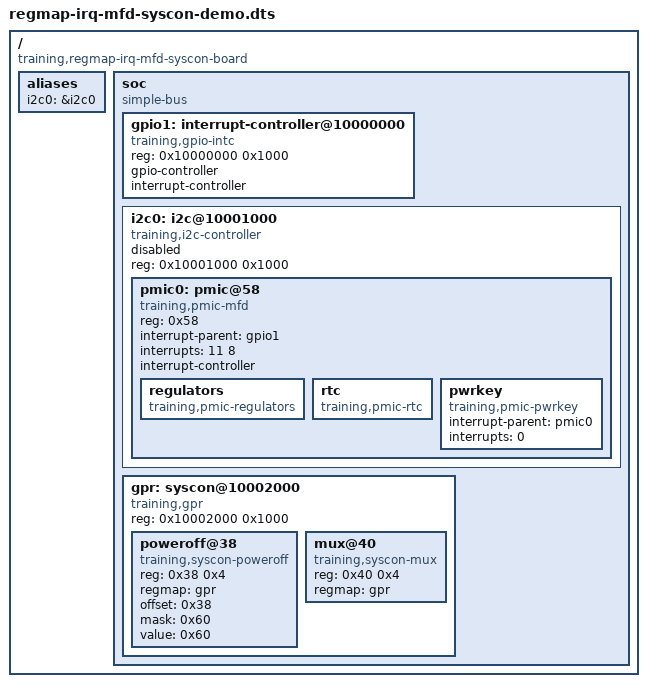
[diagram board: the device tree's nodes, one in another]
/dts-v1/;

/ {
	compatible = "training,regmap-irq-mfd-syscon-board";
	#address-cells = <1>;
	#size-cells = <1>;

	aliases {
		i2c0 = &i2c0;
	};

	soc {
		compatible = "simple-bus";
		#address-cells = <1>;
		#size-cells = <1>;
		ranges;

		gpio1: interrupt-controller@10000000 {
			compatible = "training,gpio-intc";
			reg = <0x10000000 0x1000>;
			gpio-controller;
			#gpio-cells = <2>;
			interrupt-controller;
			#interrupt-cells = <2>;
			#address-cells = <0>;
		};

		i2c0: i2c@10001000 {
			compatible = "training,i2c-controller";
			reg = <0x10001000 0x1000>;
			#address-cells = <1>;
			#size-cells = <0>;
			status = "disabled";

			pmic0: pmic@58 {
				compatible = "training,pmic-mfd";
				reg = <0x58>;
				interrupt-parent = <&gpio1>;
				interrupts = <11 8>;
				interrupt-controller;
				#interrupt-cells = <1>;
				#address-cells = <0>;

				regulators {
					compatible = "training,pmic-regulators";
				};

				rtc {
					compatible = "training,pmic-rtc";
				};

				pwrkey {
					compatible = "training,pmic-pwrkey";
					interrupt-parent = <&pmic0>;
					interrupts = <0>;
				};
			};
		};

		gpr: syscon@10002000 {
			compatible = "training,gpr", "syscon", "simple-mfd";
			reg = <0x10002000 0x1000>;
			#address-cells = <1>;
			#size-cells = <1>;

			poweroff@38 {
				compatible = "training,syscon-poweroff";
				reg = <0x38 0x4>;
				regmap = <&gpr>;
				offset = <0x38>;
				mask = <0x60>;
				value = <0x60>;
			};

			mux@40 {
				compatible = "training,syscon-mux";
				reg = <0x40 0x4>;
				regmap = <&gpr>;
			};
		};
	};
};
